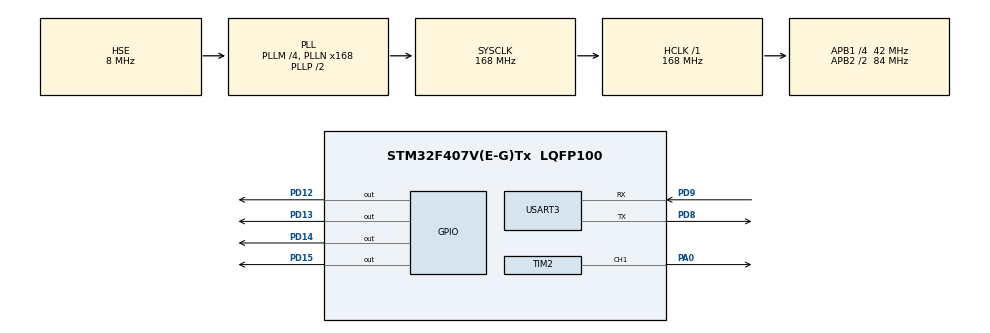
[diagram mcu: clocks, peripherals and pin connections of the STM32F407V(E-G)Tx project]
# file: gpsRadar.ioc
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Dma.Request0=USART3_RX
Dma.Request1=USART3_TX
Dma.USART3_RX.0.Direction=DMA_PERIPH_TO_MEMORY
Dma.USART3_RX.0.FIFOMode=DMA_FIFOMODE_DISABLE
Dma.USART3_RX.0.Instance=DMA1_Stream1
Dma.USART3_RX.0.MemDataAlignment=DMA_MDATAALIGN_BYTE
Dma.USART3_RX.0.MemInc=DMA_MINC_ENABLE
Dma.USART3_RX.0.Mode=DMA_CIRCULAR
Dma.USART3_RX.0.PeriphDataAlignment=DMA_PDATAALIGN_BYTE
Dma.USART3_RX.0.PeriphInc=DMA_PINC_DISABLE
Dma.USART3_RX.0.Priority=DMA_PRIORITY_LOW
Dma.USART3_TX.1.Direction=DMA_MEMORY_TO_PERIPH
Dma.USART3_TX.1.FIFOMode=DMA_FIFOMODE_DISABLE
Dma.USART3_TX.1.Instance=DMA1_Stream3
Dma.USART3_TX.1.MemDataAlignment=DMA_MDATAALIGN_BYTE
Dma.USART3_TX.1.MemInc=DMA_MINC_ENABLE
Dma.USART3_TX.1.Mode=DMA_NORMAL
Dma.USART3_TX.1.PeriphDataAlignment=DMA_PDATAALIGN_BYTE
Dma.USART3_TX.1.PeriphInc=DMA_PINC_DISABLE
Dma.USART3_TX.1.Priority=DMA_PRIORITY_LOW
FREERTOS.Mutexes01=myMutex01,Dynamic,NULL
FREERTOS.Queues01=myQueue01,16,uint16_t,0,Dynamic,NULL,NULL
FREERTOS.Tasks01=defaultTask,0,128,StartDefaultTask,Default,NULL,Dynamic,NULL,NULL
Mcu.Family=STM32F4
Mcu.Name=STM32F407V(E-G)Tx
Mcu.Package=LQFP100
NVIC.DMA1_Stream1_IRQn=true\:5\:0\:false\:false\:true\:true\:false\:true
NVIC.DMA1_Stream3_IRQn=true\:5\:0\:false\:false\:true\:true\:false\:true
NVIC.PriorityGroup=NVIC_PRIORITYGROUP_4
NVIC.TIM6_DAC_IRQn=true\:0\:0\:false\:false\:true\:false\:false\:true
NVIC.TimeBase=TIM6_DAC_IRQn
NVIC.TimeBaseIP=TIM6
NVIC.USART3_IRQn=true\:5\:0\:false\:false\:true\:true\:true\:true
PA0-WKUP.Signal=S_TIM2_CH1_ETR
PA13.Mode=Serial_Wire
PA13.Signal=SYS_JTMS-SWDIO
PA14.Mode=Serial_Wire
PA14.Signal=SYS_JTCK-SWCLK
PD12.Signal=GPIO_Output
PD13.Signal=GPIO_Output
PD14.Signal=GPIO_Output
PD15.Signal=GPIO_Output
PD8.Mode=Asynchronous
PD8.Signal=USART3_TX
PD9.Mode=Asynchronous
PD9.Signal=USART3_RX
PH0-OSC_IN.Mode=HSE-External-Oscillator
PH0-OSC_IN.Signal=RCC_OSC_IN
PH1-OSC_OUT.Mode=HSE-External-Oscillator
PH1-OSC_OUT.Signal=RCC_OSC_OUT
ProjectManager.HeapSize=0x200
ProjectManager.StackSize=0x400
ProjectManager.TargetToolchain=Makefile
RCC.48MHZClocksFreq_Value=48000000
RCC.AHBFreq_Value=168000000
RCC.APB1CLKDivider=RCC_HCLK_DIV4
RCC.APB1Freq_Value=42000000
RCC.APB1TimFreq_Value=84000000
RCC.APB2CLKDivider=RCC_HCLK_DIV2
RCC.APB2Freq_Value=84000000
RCC.APB2TimFreq_Value=168000000
RCC.CortexFreq_Value=168000000
RCC.HCLKFreq_Value=168000000
RCC.HSE_VALUE=8000000
RCC.HSI_VALUE=16000000
RCC.LSE_VALUE=32768
RCC.PLLM=4
RCC.PLLN=168
RCC.PLLQ=7
RCC.PLLSourceVirtual=RCC_PLLSOURCE_HSE
RCC.SYSCLKFreq_VALUE=168000000
RCC.SYSCLKSource=RCC_SYSCLKSOURCE_PLLCLK
RCC.VCOOutputFreq_Value=336000000
SH.S_TIM2_CH1_ETR.0=TIM2_CH1,PWM Generation1 CH1
TIM2.Channel-PWM\ Generation1\ CH1=TIM_CHANNEL_1
TIM2.Period=1000
TIM2.Pulse-PWM\ Generation1\ CH1=500
USART3.VirtualMode=VM_ASYNC
VP_FREERTOS_VS_CMSIS_V1.Mode=CMSIS_V1
VP_SYS_VS_tim6.Mode=TIM6
VP_TIM2_VS_ClockSourceINT.Mode=Internal
board=STM32F4DISCOVERY

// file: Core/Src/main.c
/* USER CODE BEGIN Header */
/**
  ******************************************************************************
  * @file           : main.c
  * @brief          : Main program body
  ******************************************************************************
  * @attention
  *
  * <h2><center>&copy; Copyright (c) 2019 STMicroelectronics.
  * All rights reserved.</center></h2>
  *
  * This software component is licensed by ST under Ultimate Liberty license
  * SLA0044, the "License"; You may not use this file except in compliance with
  * the License. You may obtain a copy of the License at:
  *                             www.st.com/SLA0044
  *
  ******************************************************************************
  */
/* USER CODE END Header */

#include "main.h"
#include "cmsis_os.h"

/* USER CODE BEGIN Includes */
#include "cpp_task1.h"
/* USER CODE END Includes */

TIM_HandleTypeDef htim2;

UART_HandleTypeDef huart3;
DMA_HandleTypeDef hdma_usart3_rx;
DMA_HandleTypeDef hdma_usart3_tx;

osThreadId defaultTaskHandle;
osMessageQId myQueue01Handle;
osMutexId myMutex01Handle;

void SystemClock_Config(void);
static void MX_GPIO_Init(void);
static void MX_DMA_Init(void);
static void MX_TIM2_Init(void);
static void MX_USART3_UART_Init(void);
void StartDefaultTask(void const * argument);

int main(void)
{

  /* MCU Configuration--------------------------------------------------------*/

  /* Reset of all peripherals, Initializes the Flash interface and the Systick. */
  HAL_Init();

  /* Configure the system clock */
  SystemClock_Config();

  /* Initialize all configured peripherals */
  MX_GPIO_Init();
  MX_DMA_Init();
  MX_TIM2_Init();
  MX_USART3_UART_Init();

  /* Create the mutex(es) */
  /* definition and creation of myMutex01 */
  osMutexDef(myMutex01);
  myMutex01Handle = osMutexCreate(osMutex(myMutex01));

  /* Create the queue(s) */
  /* definition and creation of myQueue01 */
  osMessageQDef(myQueue01, 16, uint16_t);
  myQueue01Handle = osMessageCreate(osMessageQ(myQueue01), NULL);

  /* Create the thread(s) */
  /* definition and creation of defaultTask */
  osThreadDef(defaultTask, StartDefaultTask, osPriorityNormal, 0, 128);
  defaultTaskHandle = osThreadCreate(osThread(defaultTask), NULL);

  /* Start scheduler */
  osKernelStart();

  /* We should never get here as control is now taken by the scheduler */

  /* Infinite loop */
  while (1)
  {

  }
}

void SystemClock_Config(void)
{
  RCC_OscInitTypeDef RCC_OscInitStruct = {0};
  RCC_ClkInitTypeDef RCC_ClkInitStruct = {0};

  /** Configure the main internal regulator output voltage
  */
  __HAL_RCC_PWR_CLK_ENABLE();
  __HAL_PWR_VOLTAGESCALING_CONFIG(PWR_REGULATOR_VOLTAGE_SCALE1);
  /** Initializes the CPU, AHB and APB busses clocks
  */
  RCC_OscInitStruct.OscillatorType = RCC_OSCILLATORTYPE_HSE;
  RCC_OscInitStruct.HSEState = RCC_HSE_ON;
  RCC_OscInitStruct.PLL.PLLState = RCC_PLL_ON;
  RCC_OscInitStruct.PLL.PLLSource = RCC_PLLSOURCE_HSE;
  RCC_OscInitStruct.PLL.PLLM = 4;
  RCC_OscInitStruct.PLL.PLLN = 168;
  RCC_OscInitStruct.PLL.PLLP = RCC_PLLP_DIV2;
  RCC_OscInitStruct.PLL.PLLQ = 7;
  if (HAL_RCC_OscConfig(&RCC_OscInitStruct) != HAL_OK)
  {
    Error_Handler();
  }
  /** Initializes the CPU, AHB and APB busses clocks
  */
  RCC_ClkInitStruct.ClockType = RCC_CLOCKTYPE_HCLK|RCC_CLOCKTYPE_SYSCLK
                              |RCC_CLOCKTYPE_PCLK1|RCC_CLOCKTYPE_PCLK2;
  RCC_ClkInitStruct.SYSCLKSource = RCC_SYSCLKSOURCE_PLLCLK;
  RCC_ClkInitStruct.AHBCLKDivider = RCC_SYSCLK_DIV1;
  RCC_ClkInitStruct.APB1CLKDivider = RCC_HCLK_DIV4;
  RCC_ClkInitStruct.APB2CLKDivider = RCC_HCLK_DIV2;

  if (HAL_RCC_ClockConfig(&RCC_ClkInitStruct, FLASH_LATENCY_5) != HAL_OK)
  {
    Error_Handler();
  }
}

static void MX_TIM2_Init(void)
{

  TIM_ClockConfigTypeDef sClockSourceConfig = {0};
  TIM_MasterConfigTypeDef sMasterConfig = {0};
  TIM_OC_InitTypeDef sConfigOC = {0};

  htim2.Instance = TIM2;
  htim2.Init.Prescaler = 0;
  htim2.Init.CounterMode = TIM_COUNTERMODE_UP;
  htim2.Init.Period = 1000;
  htim2.Init.ClockDivision = TIM_CLOCKDIVISION_DIV1;
  htim2.Init.AutoReloadPreload = TIM_AUTORELOAD_PRELOAD_DISABLE;
  if (HAL_TIM_Base_Init(&htim2) != HAL_OK)
  {
    Error_Handler();
  }
  sClockSourceConfig.ClockSource = TIM_CLOCKSOURCE_INTERNAL;
  if (HAL_TIM_ConfigClockSource(&htim2, &sClockSourceConfig) != HAL_OK)
  {
    Error_Handler();
  }
  if (HAL_TIM_PWM_Init(&htim2) != HAL_OK)
  {
    Error_Handler();
  }
  sMasterConfig.MasterOutputTrigger = TIM_TRGO_RESET;
  sMasterConfig.MasterSlaveMode = TIM_MASTERSLAVEMODE_DISABLE;
  if (HAL_TIMEx_MasterConfigSynchronization(&htim2, &sMasterConfig) != HAL_OK)
  {
    Error_Handler();
  }
  sConfigOC.OCMode = TIM_OCMODE_PWM1;
  sConfigOC.Pulse = 500;
  sConfigOC.OCPolarity = TIM_OCPOLARITY_HIGH;
  sConfigOC.OCFastMode = TIM_OCFAST_DISABLE;
  if (HAL_TIM_PWM_ConfigChannel(&htim2, &sConfigOC, TIM_CHANNEL_1) != HAL_OK)
  {
    Error_Handler();
  }
  HAL_TIM_MspPostInit(&htim2);

}

static void MX_USART3_UART_Init(void)
{

  huart3.Instance = USART3;
  huart3.Init.BaudRate = 115200;
  huart3.Init.WordLength = UART_WORDLENGTH_8B;
  huart3.Init.StopBits = UART_STOPBITS_1;
  huart3.Init.Parity = UART_PARITY_NONE;
  huart3.Init.Mode = UART_MODE_TX_RX;
  huart3.Init.HwFlowCtl = UART_HWCONTROL_NONE;
  huart3.Init.OverSampling = UART_OVERSAMPLING_16;
  if (HAL_UART_Init(&huart3) != HAL_OK)
  {
    Error_Handler();
  }

}

static void MX_DMA_Init(void)
{
  /* DMA controller clock enable */
  __HAL_RCC_DMA1_CLK_ENABLE();

  /* DMA interrupt init */
  /* DMA1_Stream1_IRQn interrupt configuration */
  HAL_NVIC_SetPriority(DMA1_Stream1_IRQn, 5, 0);
  HAL_NVIC_EnableIRQ(DMA1_Stream1_IRQn);
  /* DMA1_Stream3_IRQn interrupt configuration */
  HAL_NVIC_SetPriority(DMA1_Stream3_IRQn, 5, 0);
  HAL_NVIC_EnableIRQ(DMA1_Stream3_IRQn);

}

static void MX_GPIO_Init(void)
{
  GPIO_InitTypeDef GPIO_InitStruct = {0};

  /* GPIO Ports Clock Enable */
  __HAL_RCC_GPIOH_CLK_ENABLE();
  __HAL_RCC_GPIOA_CLK_ENABLE();
  __HAL_RCC_GPIOD_CLK_ENABLE();

  /*Configure GPIO pin Output Level */
  HAL_GPIO_WritePin(GPIOD, GPIO_PIN_12|GPIO_PIN_13|GPIO_PIN_14|GPIO_PIN_15, GPIO_PIN_RESET);

  /*Configure GPIO pins : PD12 PD13 PD14 PD15 */
  GPIO_InitStruct.Pin = GPIO_PIN_12|GPIO_PIN_13|GPIO_PIN_14|GPIO_PIN_15;
  GPIO_InitStruct.Mode = GPIO_MODE_OUTPUT_PP;
  GPIO_InitStruct.Pull = GPIO_NOPULL;
  GPIO_InitStruct.Speed = GPIO_SPEED_FREQ_LOW;
  HAL_GPIO_Init(GPIOD, &GPIO_InitStruct);

}

void StartDefaultTask(void const * argument)
{

  /* USER CODE BEGIN 5 */
  start_cpp_task1(&htim2, &huart3);
	// HAL_TIM_PWM_Start(&htim2, TIM_CHANNEL_1);
  /* Infinite loop */
	for(;;)
	{
    // HAL_GPIO_TogglePin(GPIOD, GPIO_PIN_14);

		// osDelay(1000);
    // htim2.Instance->ARR = 200;
    // htim2.Instance->CCR1 = 100;
    // htim2.Instance->CNT = 1;

    // osDelay(1000);
    // htim2.Instance->ARR = 1000;
    // htim2.Instance->CCR1 = 500;
    // htim2.Instance->CNT = 1;

	}
  /* USER CODE END 5 */
}

void HAL_TIM_PeriodElapsedCallback(TIM_HandleTypeDef *htim)
{
  if (htim->Instance == TIM6) {
    HAL_IncTick();
  }
}

void Error_Handler(void)
{
}

/************************ (C) COPYRIGHT STMicroelectronics *****END OF FILE****/
